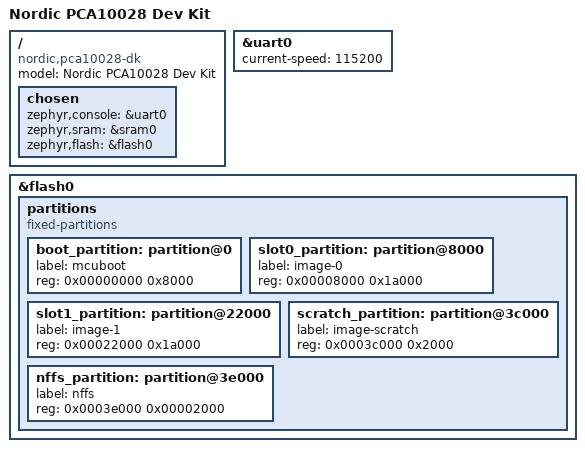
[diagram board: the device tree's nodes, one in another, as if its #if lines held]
/*
 * Copyright (c) 2017 Linaro Limited
 *
 * SPDX-License-Identifier: Apache-2.0
 */

/dts-v1/;
#include <nordic/nrf51822.dtsi>

/ {
	model = "Nordic PCA10028 Dev Kit";
	compatible = "nordic,pca10028-dk", "nordic,nrf51822-qfac",
		     "nordic,nrf51822";

	chosen {
		zephyr,console = &uart0;
		zephyr,sram = &sram0;
		zephyr,flash = &flash0;
	};
};

&uart0 {
	current-speed = <115200>;
	status = "ok";
};

&flash0 {
	/*
	 * If chosen's zephyr,code-partition
	 * is unset, the image will be linked
	 * into the entire flash device.  If
	 * it points to an individual
	 * partition, the code will be linked
	 * to, and restricted to that
	 * partition.
	 */
	partitions {
		compatible = "fixed-partitions";
		#address-cells = <1>;
		#size-cells = <1>;

		boot_partition: partition@0 {
			label = "mcuboot";
			reg = <0x00000000 0x8000>;
		};
		slot0_partition: partition@8000 {
			label = "image-0";
			reg = <0x00008000 0x1a000>;
		};
		slot1_partition: partition@22000 {
			label = "image-1";
			reg = <0x00022000 0x1a000>;
		};
		scratch_partition: partition@3c000 {
			label = "image-scratch";
			reg = <0x0003c000 0x2000>;
		};

		/*
		 * The flash starting at 0x0003e000 and ending at
		 * 0x0003ffff is reserved for use by the application.
		 * If enabled, partition for NFFS will be created in
		 * this area.
		 */

#if defined(CONFIG_FILE_SYSTEM_NFFS)
		nffs_partition: partition@3e000 {
			label = "nffs";
			reg = <0x0003e000 0x00002000>;
		};
#endif
	};
};
